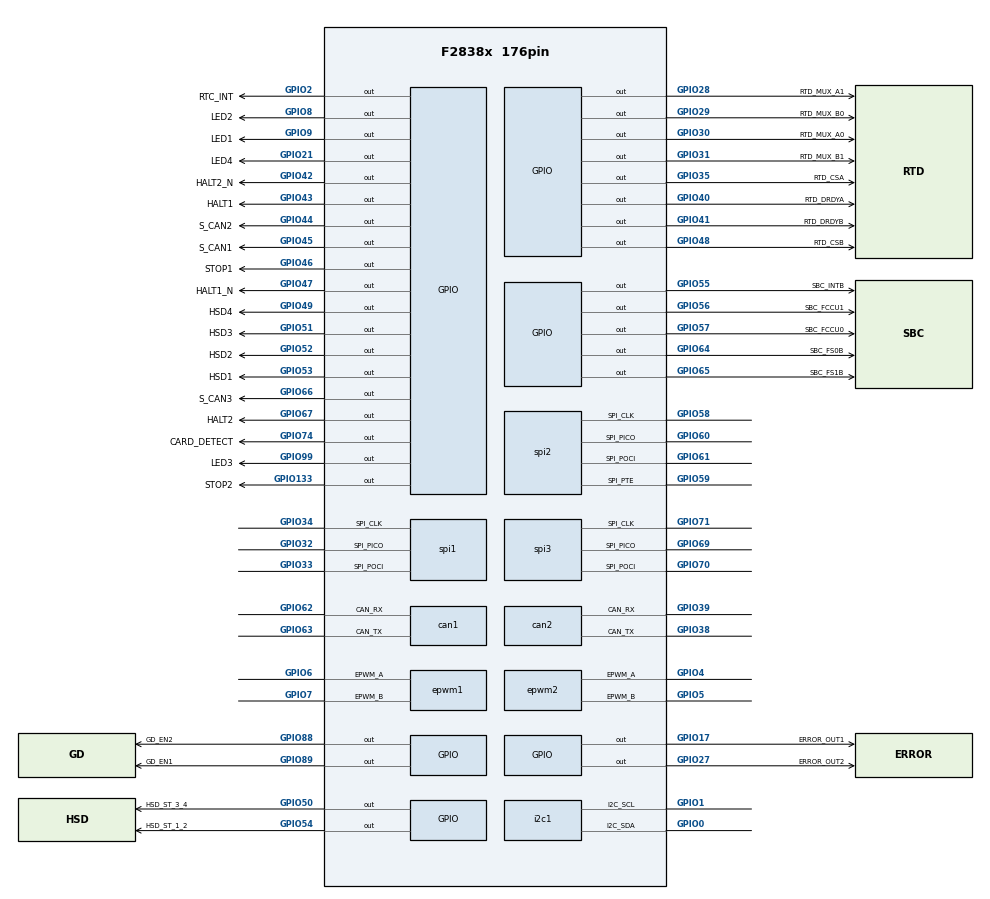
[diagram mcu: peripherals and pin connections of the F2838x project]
/**
 * @cliArgs --device "F2838x" --package "176pin" --part "F2838x_176pin" --context "CPU1" --product "C2000WARE@5.02.00.00"
 * @versions {"tool":"1.19.0+3426"}
 */

/**
 * Import the modules used in this configuration.
 */
const adc            = scripting.addModule("/driverlib/adc.js", {}, false);
const adc1           = adc.addInstance();
const adc2           = adc.addInstance();
const adc3           = adc.addInstance();
const adc4           = adc.addInstance();
const asysctl        = scripting.addModule("/driverlib/asysctl.js");
const can            = scripting.addModule("/driverlib/can.js", {}, false);
const can1           = can.addInstance();
const can2           = can.addInstance();
const cla            = scripting.addModule("/driverlib/cla.js", {}, false);
const cla1           = cla.addInstance();
const device_support = scripting.addModule("/driverlib/device_support.js");
const epwm           = scripting.addModule("/driverlib/epwm.js", {}, false);
const epwm1          = epwm.addInstance();
const epwm2          = epwm.addInstance();
const epwm3          = epwm.addInstance();
const epwm4          = epwm.addInstance();
const gpio           = scripting.addModule("/driverlib/gpio.js", {}, false);
const gpio1          = gpio.addInstance();
const gpio2          = gpio.addInstance();
const gpio3          = gpio.addInstance();
const gpio4          = gpio.addInstance();
const gpio5          = gpio.addInstance();
const gpio6          = gpio.addInstance();
const gpio7          = gpio.addInstance();
const gpio8          = gpio.addInstance();
const gpio9          = gpio.addInstance();
const gpio10         = gpio.addInstance();
const gpio11         = gpio.addInstance();
const gpio12         = gpio.addInstance();
const gpio13         = gpio.addInstance();
const gpio14         = gpio.addInstance();
const gpio15         = gpio.addInstance();
const gpio16         = gpio.addInstance();
const gpio17         = gpio.addInstance();
const gpio18         = gpio.addInstance();
const gpio19         = gpio.addInstance();
const gpio20         = gpio.addInstance();
const gpio21         = gpio.addInstance();
const gpio22         = gpio.addInstance();
const gpio23         = gpio.addInstance();
const gpio24         = gpio.addInstance();
const gpio25         = gpio.addInstance();
const gpio26         = gpio.addInstance();
const gpio27         = gpio.addInstance();
const gpio28         = gpio.addInstance();
const gpio29         = gpio.addInstance();
const gpio30         = gpio.addInstance();
const gpio31         = gpio.addInstance();
const gpio32         = gpio.addInstance();
const gpio33         = gpio.addInstance();
const gpio34         = gpio.addInstance();
const gpio35         = gpio.addInstance();
const gpio36         = gpio.addInstance();
const gpio37         = gpio.addInstance();
const gpio38         = gpio.addInstance();
const i2c            = scripting.addModule("/driverlib/i2c.js", {}, false);
const i2c1           = i2c.addInstance();
const ipc            = scripting.addModule("/driverlib/ipc.js");
const memcfg         = scripting.addModule("/driverlib/memcfg.js");
const spi            = scripting.addModule("/driverlib/spi.js", {}, false);
const spi1           = spi.addInstance();
const spi2           = spi.addInstance();
const spi3           = spi.addInstance();
const sync           = scripting.addModule("/driverlib/sync.js");
const sysctl         = scripting.addModule("/driverlib/sysctl.js");
const FREERTOS       = scripting.addModule("/kernel/freertos_tool/FREERTOS", {}, false);
const FREERTOS1      = FREERTOS.addInstance();
const FPUfastRTS     = scripting.addModule("/libraries/math/FPUfastRTS/FPUfastRTS.js", {}, false);
const FPUfastRTS1    = FPUfastRTS.addInstance();
const CMD            = scripting.addModule("/utilities/cmd_tool/cmd_syscfg/source/CMD");
const CMD1           = CMD.addInstance();

/**
 * Write custom configuration values to the imported modules.
 */
adc1.$name                   = "myADCA";
adc1.adcClockPrescaler       = "ADC_CLK_DIV_4_0";
adc1.adcResolutionMode       = "ADC_RESOLUTION_16BIT";
adc1.adcSignalMode           = "ADC_MODE_DIFFERENTIAL";
adc1.socHighPriorityMode     = "ADC_PRI_ALL_HIPRI";
adc1.enabledSOCs             = ["ADC_SOC_NUMBER0","ADC_SOC_NUMBER1"];
adc1.soc0Channel             = "ADC_CH_ADCIN2_ADCIN3";
adc1.soc0Trigger             = "ADC_TRIGGER_EPWM4_SOCA";
adc1.soc0SampleWindow        = 96;
adc1.soc1Channel             = "ADC_CH_ADCIN4_ADCIN5";
adc1.soc1Trigger             = "ADC_TRIGGER_EPWM4_SOCA";
adc1.soc1SampleWindow        = 96;
adc1.interruptPulseMode      = "ADC_PULSE_END_OF_CONV";
adc1.enabledInts             = ["ADC_INT_NUMBER1"];
adc1.enableInterrupt1        = true;
adc1.interrupt1SOCSource     = "ADC_SOC_NUMBER1";
adc1.registerInterrupts      = ["1"];
adc1.adcInt1.enableInterrupt = true;

adc2.$name                   = "myADCB";
adc2.adcBase                 = "ADCB_BASE";
adc2.adcClockPrescaler       = "ADC_CLK_DIV_4_0";
adc2.adcResolutionMode       = "ADC_RESOLUTION_16BIT";
adc2.socHighPriorityMode     = "ADC_PRI_ALL_HIPRI";
adc2.enabledSOCs             = ["ADC_SOC_NUMBER0","ADC_SOC_NUMBER1","ADC_SOC_NUMBER2","ADC_SOC_NUMBER3"];
adc2.soc0Channel             = "ADC_CH_ADCIN3";
adc2.soc0Trigger             = "ADC_TRIGGER_EPWM4_SOCA";
adc2.soc0SampleWindow        = 96;
adc2.soc1SampleWindow        = 96;
adc2.soc1Trigger             = "ADC_TRIGGER_EPWM4_SOCA";
adc2.soc1Channel             = "ADC_CH_ADCIN8";
adc2.soc2Channel             = "ADC_CH_ADCIN2";
adc2.soc2SampleWindow        = 96;
adc2.soc2Trigger             = "ADC_TRIGGER_EPWM4_SOCA";
adc2.soc3Channel             = "ADC_CH_ADCIN9";
adc2.soc3Trigger             = "ADC_TRIGGER_EPWM4_SOCA";
adc2.soc3SampleWindow        = 96;
adc2.interruptPulseMode      = "ADC_PULSE_END_OF_CONV";
adc2.enabledInts             = ["ADC_INT_NUMBER1"];
adc2.enableInterrupt1        = true;
adc2.interrupt1SOCSource     = "ADC_SOC_NUMBER3";
adc2.registerInterrupts      = ["1"];
adc2.adcInt1.enableInterrupt = true;

adc3.$name                   = "myADCC";
adc3.adcBase                 = "ADCC_BASE";
adc3.adcClockPrescaler       = "ADC_CLK_DIV_4_0";
adc3.adcResolutionMode       = "ADC_RESOLUTION_16BIT";
adc3.adcSignalMode           = "ADC_MODE_DIFFERENTIAL";
adc3.socHighPriorityMode     = "ADC_PRI_ALL_HIPRI";
adc3.enabledSOCs             = ["ADC_SOC_NUMBER0","ADC_SOC_NUMBER1"];
adc3.soc0Channel             = "ADC_CH_ADCIN2_ADCIN3";
adc3.soc0SampleWindow        = 96;
adc3.soc0Trigger             = "ADC_TRIGGER_EPWM4_SOCA";
adc3.soc1Channel             = "ADC_CH_ADCIN4_ADCIN5";
adc3.soc1SampleWindow        = 96;
adc3.soc1Trigger             = "ADC_TRIGGER_EPWM4_SOCA";
adc3.interruptPulseMode      = "ADC_PULSE_END_OF_CONV";
adc3.enabledInts             = ["ADC_INT_NUMBER1"];
adc3.enableInterrupt1        = true;
adc3.interrupt1SOCSource     = "ADC_SOC_NUMBER1";
adc3.registerInterrupts      = ["1"];
adc3.adcInt1.enableInterrupt = true;

adc4.adcBase                 = "ADCD_BASE";
adc4.$name                   = "myADCD";
adc4.adcClockPrescaler       = "ADC_CLK_DIV_4_0";
adc4.adcResolutionMode       = "ADC_RESOLUTION_16BIT";
adc4.socHighPriorityMode     = "ADC_PRI_ALL_HIPRI";
adc4.enabledSOCs             = ["ADC_SOC_NUMBER0","ADC_SOC_NUMBER1","ADC_SOC_NUMBER2","ADC_SOC_NUMBER3","ADC_SOC_NUMBER4","ADC_SOC_NUMBER5"];
adc4.soc0Channel             = "ADC_CH_ADCIN1";
adc4.soc0Trigger             = "ADC_TRIGGER_EPWM4_SOCA";
adc4.soc0SampleWindow        = 96;
adc4.soc1Channel             = "ADC_CH_ADCIN8";
adc4.soc1SampleWindow        = 96;
adc4.soc1Trigger             = "ADC_TRIGGER_EPWM4_SOCA";
adc4.soc2SampleWindow        = 96;
adc4.soc2Trigger             = "ADC_TRIGGER_EPWM4_SOCA";
adc4.soc3Trigger             = "ADC_TRIGGER_EPWM4_SOCA";
adc4.soc3SampleWindow        = 96;
adc4.soc3Channel             = "ADC_CH_ADCIN9";
adc4.soc4Channel             = "ADC_CH_ADCIN2";
adc4.soc4Trigger             = "ADC_TRIGGER_EPWM4_SOCA";
adc4.soc4SampleWindow        = 96;
adc4.soc5Channel             = "ADC_CH_ADCIN9";
adc4.soc5SampleWindow        = 96;
adc4.soc5Trigger             = "ADC_TRIGGER_EPWM4_SOCA";
adc4.interruptPulseMode      = "ADC_PULSE_END_OF_CONV";
adc4.enabledInts             = ["ADC_INT_NUMBER1"];
adc4.enableInterrupt1        = true;
adc4.registerInterrupts      = ["1"];
adc4.interrupt1SOCSource     = "ADC_SOC_NUMBER5";
adc4.adcInt1.enableInterrupt = true;

asysctl.enableTemperatureSensor = true;

can1.msgObjsUsed           = [1,2,3,4,5,6];
can1.registerInterrupts    = true;
can1.interruptFlags        = ["CAN_INT_ERROR","CAN_INT_IE0","CAN_INT_STATUS"];
can1.interruptLine         = ["CAN_GLOBAL_INT_CANINT0"];
can1.$name                 = "CAN1";
can1.can.$assign           = "CANA";
can1.can.can_rxPin.$assign = "GPIO62";
can1.can.can_txPin.$assign = "GPIO63";
can1.msgObj1.$name         = "msgObj0";
can1.msgObj1.msgID         = 1580;
can1.msgObj1.msgType       = "CAN_MSG_OBJ_TYPE_TX";
can1.msgObj1.flags         = ["CAN_MSG_OBJ_TX_INT_ENABLE"];
can1.msgObj1.msgLen        = 8;
can1.msgObj2.$name         = "msgObj1";
can1.msgObj2.msgID         = 1452;
can1.msgObj2.flags         = ["CAN_MSG_OBJ_RX_INT_ENABLE"];
can1.msgObj3.$name         = "msgObj2";
can1.msgObj3.msgID         = 1581;
can1.msgObj3.msgType       = "CAN_MSG_OBJ_TYPE_TX";
can1.msgObj3.flags         = ["CAN_MSG_OBJ_TX_INT_ENABLE"];
can1.msgObj3.msgLen        = 8;
can1.msgObj4.$name         = "msgObj3";
can1.msgObj4.msgID         = 1453;
can1.msgObj4.flags         = ["CAN_MSG_OBJ_RX_INT_ENABLE"];
can1.msgObj5.$name         = "msgObj4";
can1.msgObj5.msgID         = 1836;
can1.msgObj5.flags         = ["CAN_MSG_OBJ_RX_INT_ENABLE"];
can1.msgObj6.$name         = "msgObj5";
can1.msgObj6.msgID         = 1837;
can1.msgObj6.flags         = ["CAN_MSG_OBJ_RX_INT_ENABLE"];

can2.msgObjsUsed           = [1,2,3,4,5,6,7,8,9,10,11,12,13,14,15,16];
can2.enableInterrupt       = true;
can2.registerInterrupts    = true;
can2.interruptFlags        = ["CAN_INT_ERROR","CAN_INT_IE0","CAN_INT_STATUS"];
can2.interruptLine         = ["CAN_GLOBAL_INT_CANINT0"];
can2.$name                 = "CAN2";
can2.can.$assign           = "CANB";
can2.can.can_rxPin.$assign = "GPIO39";
can2.can.can_txPin.$assign = "GPIO38";
can2.msgObj1.$name         = "msgObj6";
can2.msgObj1.msgID         = 660;
can2.msgObj1.flags         = ["CAN_MSG_OBJ_RX_INT_ENABLE"];
can2.msgObj2.$name         = "msgObj7";
can2.msgObj2.msgID         = 661;
can2.msgObj2.flags         = ["CAN_MSG_OBJ_RX_INT_ENABLE"];
can2.msgObj3.$name         = "msgObj8";
can2.msgObj3.msgID         = 662;
can2.msgObj3.msgType       = "CAN_MSG_OBJ_TYPE_TX";
can2.msgObj3.flags         = ["CAN_MSG_OBJ_TX_INT_ENABLE"];
can2.msgObj3.msgLen        = 8;
can2.msgObj4.$name         = "msgObj9";
can2.msgObj4.msgID         = 663;
can2.msgObj4.flags         = ["CAN_MSG_OBJ_RX_INT_ENABLE"];
can2.msgObj5.$name         = "msgObj12";
can2.msgObj5.msgID         = 664;
can2.msgObj5.msgType       = "CAN_MSG_OBJ_TYPE_TX";
can2.msgObj5.flags         = ["CAN_MSG_OBJ_TX_INT_ENABLE"];
can2.msgObj5.msgLen        = 8;
can2.msgObj6.$name         = "msgObj10";
can2.msgObj6.msgID         = 665;
can2.msgObj6.msgType       = "CAN_MSG_OBJ_TYPE_TX";
can2.msgObj6.flags         = ["CAN_MSG_OBJ_TX_INT_ENABLE"];
can2.msgObj6.msgLen        = 8;
can2.msgObj7.$name         = "msgObj11";
can2.msgObj7.msgID         = 666;
can2.msgObj7.msgType       = "CAN_MSG_OBJ_TYPE_TX";
can2.msgObj7.msgLen        = 8;
can2.msgObj7.flags         = ["CAN_MSG_OBJ_TX_INT_ENABLE"];
can2.msgObj8.$name         = "msgObj13";
can2.msgObj8.msgID         = 667;
can2.msgObj8.msgType       = "CAN_MSG_OBJ_TYPE_TX";
can2.msgObj8.flags         = ["CAN_MSG_OBJ_TX_INT_ENABLE"];
can2.msgObj8.msgLen        = 8;
can2.msgObj9.$name         = "msgObj14";
can2.msgObj9.msgID         = 668;
can2.msgObj9.msgType       = "CAN_MSG_OBJ_TYPE_TX";
can2.msgObj9.flags         = ["CAN_MSG_OBJ_TX_INT_ENABLE"];
can2.msgObj9.msgLen        = 6;
can2.msgObj10.$name        = "msgObj15";
can2.msgObj10.msgID        = 669;
can2.msgObj10.msgType      = "CAN_MSG_OBJ_TYPE_TX";
can2.msgObj10.flags        = ["CAN_MSG_OBJ_TX_INT_ENABLE"];
can2.msgObj10.msgLen       = 6;
can2.msgObj11.$name        = "msgObj16";
can2.msgObj11.msgID        = 670;
can2.msgObj11.msgType      = "CAN_MSG_OBJ_TYPE_TX";
can2.msgObj11.flags        = ["CAN_MSG_OBJ_TX_INT_ENABLE"];
can2.msgObj11.msgLen       = 7;
can2.msgObj12.$name        = "msgObj18";
can2.msgObj12.msgID        = 671;
can2.msgObj12.msgType      = "CAN_MSG_OBJ_TYPE_TX";
can2.msgObj12.flags        = ["CAN_MSG_OBJ_TX_INT_ENABLE"];
can2.msgObj12.msgLen       = 7;
can2.msgObj13.$name        = "msgObj17";
can2.msgObj13.msgID        = 672;
can2.msgObj13.msgType      = "CAN_MSG_OBJ_TYPE_TX";
can2.msgObj13.flags        = ["CAN_MSG_OBJ_TX_INT_ENABLE"];
can2.msgObj13.msgLen       = 8;
can2.msgObj14.$name        = "msgObj19";
can2.msgObj14.msgID        = 673;
can2.msgObj14.msgType      = "CAN_MSG_OBJ_TYPE_TX";
can2.msgObj14.flags        = ["CAN_MSG_OBJ_TX_INT_ENABLE"];
can2.msgObj14.msgLen       = 8;
can2.msgObj15.$name        = "msgObj20";
can2.msgObj15.msgID        = 674;
can2.msgObj15.msgType      = "CAN_MSG_OBJ_TYPE_TX";
can2.msgObj15.flags        = ["CAN_MSG_OBJ_TX_INT_ENABLE"];
can2.msgObj15.msgLen       = 8;
can2.msgObj16.$name        = "msgObj21";
can2.msgObj16.msgID        = 675;
can2.msgObj16.msgType      = "CAN_MSG_OBJ_TYPE_TX";
can2.msgObj16.flags        = ["CAN_MSG_OBJ_TX_INT_ENABLE"];
can2.msgObj16.msgLen       = 8;

cla1.$name = "myCLA0";

const multiplier1         = system.clockTree["AUX_IMULT"];
multiplier1.multiplyValue = 50;

const multiplier2         = system.clockTree["PLL_IMULT"];
multiplier2.multiplyValue = 40;

const mux18       = system.clockTree["XTAL_OR_X1"];
mux18.inputSelect = "XTAL";

const pinFunction3     = system.clockTree["XTAL"];
pinFunction3.XTAL_Freq = 20;

epwm1.$name                                                      = "GD_HB_1";
epwm1.epwmTimebase_hsClockDiv                                    = "EPWM_HSCLOCK_DIVIDER_1";
epwm1.epwmTimebase_period                                        = 25000;
epwm1.epwmTimebase_counterValue                                  = 17000;
epwm1.epwmTimebase_counterMode                                   = "EPWM_COUNTER_MODE_UP_DOWN";
epwm1.epwmTimebase_syncInPulseSource                             = "EPWM_SYNC_IN_PULSE_SRC_DISABLE";
epwm1.epwmTimebase_syncOutPulseMode                              = ["EPWM_SYNC_OUT_PULSE_ON_SOFTWARE"];
epwm1.epwmCounterCompare_cmpA                                    = 1000;
epwm1.epwmCounterCompare_cmpB                                    = 1000;
epwm1.epwmActionQualifier_EPWM_AQ_OUTPUT_A_shadowMode            = true;
epwm1.epwmActionQualifier_EPWM_AQ_OUTPUT_A_ON_TIMEBASE_UP_CMPA   = "EPWM_AQ_OUTPUT_HIGH";
epwm1.epwmActionQualifier_EPWM_AQ_OUTPUT_A_ON_TIMEBASE_DOWN_CMPB = "EPWM_AQ_OUTPUT_LOW";
epwm1.epwmActionQualifier_EPWM_AQ_OUTPUT_B_shadowMode            = true;
epwm1.epwmActionQualifier_EPWM_AQ_OUTPUT_B_ON_TIMEBASE_UP_CMPA   = "EPWM_AQ_OUTPUT_LOW";
epwm1.epwmActionQualifier_EPWM_AQ_OUTPUT_B_ON_TIMEBASE_DOWN_CMPB = "EPWM_AQ_OUTPUT_HIGH";
epwm1.epwmDeadband_polarityFED                                   = "EPWM_DB_POLARITY_ACTIVE_LOW";
epwm1.epwmDeadband_enableRED                                     = true;
epwm1.epwmDeadband_delayRED                                      = 800;
epwm1.epwmDeadband_enableFED                                     = true;
epwm1.epwmDeadband_delayFED                                      = 800;
epwm1.epwmEventTrigger_enableInterrupt                           = true;
epwm1.epwmEventTrigger_registerInterrupts                        = true;
epwm1.epwmEventTrigger_interruptSource                           = "EPWM_INT_TBCTR_PERIOD";
epwm1.epwmEventTrigger_interruptEventCount                       = "1";
epwm1.epwmEventTrigger_EPWM_SOC_A_triggerEnable                  = true;
epwm1.epwmEventTrigger_EPWM_SOC_A_triggerSource                  = "EPWM_SOC_TBCTR_PERIOD";
epwm1.epwmEventTrigger_EPWM_SOC_A_triggerEventPrescalar          = "1";
epwm1.epwmEventTrigger_EPWM_SOC_B_triggerEnable                  = true;
epwm1.epwmEventTrigger_EPWM_SOC_B_triggerSource                  = "EPWM_SOC_TBCTR_PERIOD";
epwm1.epwmEventTrigger_EPWM_SOC_B_triggerEventPrescalar          = "1";
epwm1.epwmTripZone_EPWM_TZ_ACTION_EVENT_TZB                      = "EPWM_TZ_ACTION_LOW";
epwm1.epwmTripZone_oneShotSource                                 = ["EPWM_TZ_SIGNAL_OSHT1"];
epwm1.epwmTripZone_tzInterruptSource                             = ["EPWM_TZ_INTERRUPT_OST"];
epwm1.epwmTripZone_EPWM_TZ_ACTION_EVENT_TZA                      = "EPWM_TZ_ACTION_HIGH";
epwm1.epwm.$assign                                               = "EPWM4";
epwm1.epwm.epwm_aPin.$assign                                     = "GPIO6";
epwm1.epwm.epwm_bPin.$assign                                     = "GPIO7";
epwm1.epwmInt.enableInterrupt                                    = true;

epwm2.$name                                                      = "GD_HB_2";
epwm2.epwmTimebase_hsClockDiv                                    = "EPWM_HSCLOCK_DIVIDER_1";
epwm2.epwmTimebase_counterMode                                   = "EPWM_COUNTER_MODE_UP_DOWN";
epwm2.epwmTimebase_syncInPulseSource                             = "EPWM_SYNC_IN_PULSE_SRC_SYNCOUT_EPWM4";
epwm2.epwmTimebase_syncOutPulseMode                              = ["EPWM_SYNC_OUT_PULSE_ON_SOFTWARE"];
epwm2.epwmCounterCompare_cmpA                                    = 1000;
epwm2.epwmCounterCompare_cmpB                                    = 1000;
epwm2.epwmTimebase_period                                        = 2500;
epwm2.epwmDeadband_enableRED                                     = true;
epwm2.epwmDeadband_delayRED                                      = 560;
epwm2.epwmDeadband_delayFED                                      = 520;
epwm2.epwmDeadband_enableFED                                     = true;
epwm2.epwmDeadband_polarityFED                                   = "EPWM_DB_POLARITY_ACTIVE_LOW";
epwm2.epwmEventTrigger_enableInterrupt                           = true;
epwm2.epwmEventTrigger_registerInterrupts                        = true;
epwm2.epwmActionQualifier_EPWM_AQ_OUTPUT_A_ON_TIMEBASE_UP_CMPA   = "EPWM_AQ_OUTPUT_HIGH";
epwm2.epwmActionQualifier_EPWM_AQ_OUTPUT_A_ON_TIMEBASE_DOWN_CMPB = "EPWM_AQ_OUTPUT_LOW";
epwm2.epwmActionQualifier_EPWM_AQ_OUTPUT_A_shadowMode            = true;
epwm2.epwmActionQualifier_EPWM_AQ_OUTPUT_B_shadowMode            = true;
epwm2.epwmActionQualifier_EPWM_AQ_OUTPUT_B_ON_TIMEBASE_UP_CMPA   = "EPWM_AQ_OUTPUT_LOW";
epwm2.epwmActionQualifier_EPWM_AQ_OUTPUT_B_ON_TIMEBASE_DOWN_CMPB = "EPWM_AQ_OUTPUT_HIGH";
epwm2.epwmTripZone_EPWM_TZ_ACTION_EVENT_TZA                      = "EPWM_TZ_ACTION_LOW";
epwm2.epwmTripZone_oneShotSource                                 = ["EPWM_TZ_SIGNAL_OSHT1"];
epwm2.epwmTripZone_EPWM_TZ_ACTION_EVENT_TZB                      = "EPWM_TZ_ACTION_HIGH";
epwm2.epwm.$assign                                               = "EPWM3";
epwm2.epwm.epwm_aPin.$assign                                     = "GPIO4";
epwm2.epwm.epwm_bPin.$assign                                     = "GPIO5";
epwm2.epwmInt.enableInterrupt                                    = true;

epwm3.$name                                                      = "FO_HB_1";
epwm3.epwmTimebase_hsClockDiv                                    = "EPWM_HSCLOCK_DIVIDER_1";
epwm3.epwmTimebase_period                                        = 25000;
epwm3.epwmTimebase_counterMode                                   = "EPWM_COUNTER_MODE_UP_DOWN";
epwm3.epwmTimebase_syncInPulseSource                             = "EPWM_SYNC_IN_PULSE_SRC_SYNCOUT_EPWM4";
epwm3.epwmTimebase_syncOutPulseMode                              = ["EPWM_SYNC_OUT_PULSE_ON_SOFTWARE"];
epwm3.epwmCounterCompare_cmpA                                    = 1000;
epwm3.epwmCounterCompare_cmpB                                    = 1000;
epwm3.epwmEventTrigger_enableInterrupt                           = true;
epwm3.epwmEventTrigger_registerInterrupts                        = true;
epwm3.epwmEventTrigger_interruptEventCount                       = "1";
epwm3.epwmEventTrigger_interruptSource                           = "EPWM_INT_TBCTR_PERIOD";
epwm3.useCase                                                    = "CUSTOM";
epwm3.epwmDeadband_enableRED                                     = true;
epwm3.epwmDeadband_enableFED                                     = true;
epwm3.epwmDeadband_delayRED                                      = 560;
epwm3.epwmDeadband_delayFED                                      = 520;
epwm3.epwmDeadband_polarityRED                                   = "EPWM_DB_POLARITY_ACTIVE_LOW";
epwm3.epwmTripZone_EPWM_TZ_ACTION_EVENT_TZA                      = "EPWM_TZ_ACTION_LOW";
epwm3.epwmTripZone_EPWM_TZ_ACTION_EVENT_TZB                      = "EPWM_TZ_ACTION_HIGH";
epwm3.epwmActionQualifier_EPWM_AQ_OUTPUT_B_ON_TIMEBASE_UP_CMPA   = "EPWM_AQ_OUTPUT_HIGH";
epwm3.epwmActionQualifier_EPWM_AQ_OUTPUT_A_ON_TIMEBASE_UP_CMPA   = "EPWM_AQ_OUTPUT_LOW";
epwm3.epwmActionQualifier_EPWM_AQ_OUTPUT_A_ON_TIMEBASE_DOWN_CMPB = "EPWM_AQ_OUTPUT_HIGH";
epwm3.epwmActionQualifier_EPWM_AQ_OUTPUT_B_ON_TIMEBASE_DOWN_CMPB = "EPWM_AQ_OUTPUT_LOW";
epwm3.epwmActionQualifier_EPWM_AQ_OUTPUT_B_shadowMode            = true;
epwm3.epwmActionQualifier_EPWM_AQ_OUTPUT_A_shadowMode            = true;
epwm3.epwmInt.enableInterrupt                                    = true;
epwm3.epwm.$assign                                               = "EPWM12";

epwm4.$name                                                      = "FO_HB_2";
epwm4.epwmTimebase_hsClockDiv                                    = "EPWM_HSCLOCK_DIVIDER_1";
epwm4.epwmTimebase_period                                        = 25000;
epwm4.epwmTimebase_counterMode                                   = "EPWM_COUNTER_MODE_UP_DOWN";
epwm4.epwmTimebase_syncInPulseSource                             = "EPWM_SYNC_IN_PULSE_SRC_SYNCOUT_EPWM4";
epwm4.epwmTimebase_syncOutPulseMode                              = ["EPWM_SYNC_OUT_PULSE_ON_SOFTWARE"];
epwm4.epwmCounterCompare_cmpA                                    = 1000;
epwm4.epwmCounterCompare_cmpB                                    = 1000;
epwm4.epwmActionQualifier_EPWM_AQ_OUTPUT_A_shadowMode            = true;
epwm4.epwmActionQualifier_EPWM_AQ_OUTPUT_A_ON_TIMEBASE_UP_CMPA   = "EPWM_AQ_OUTPUT_LOW";
epwm4.epwmActionQualifier_EPWM_AQ_OUTPUT_A_ON_TIMEBASE_DOWN_CMPB = "EPWM_AQ_OUTPUT_HIGH";
epwm4.epwmActionQualifier_EPWM_AQ_OUTPUT_B_shadowMode            = true;
epwm4.epwmActionQualifier_EPWM_AQ_OUTPUT_B_ON_TIMEBASE_UP_CMPA   = "EPWM_AQ_OUTPUT_HIGH";
epwm4.epwmActionQualifier_EPWM_AQ_OUTPUT_B_ON_TIMEBASE_DOWN_CMPB = "EPWM_AQ_OUTPUT_LOW";
epwm4.epwmDeadband_enableRED                                     = true;
epwm4.epwmDeadband_delayRED                                      = 560;
epwm4.epwmDeadband_delayFED                                      = 520;
epwm4.epwmDeadband_enableFED                                     = true;
epwm4.epwmTripZone_EPWM_TZ_ACTION_EVENT_TZA                      = "EPWM_TZ_ACTION_LOW";
epwm4.epwmTripZone_EPWM_TZ_ACTION_EVENT_TZB                      = "EPWM_TZ_ACTION_HIGH";
epwm4.epwmTripZone_oneShotSource                                 = ["EPWM_TZ_SIGNAL_OSHT1"];
epwm4.epwmEventTrigger_enableInterrupt                           = true;
epwm4.epwmEventTrigger_registerInterrupts                        = true;
epwm4.epwmEventTrigger_EPWM_SOC_A_triggerEnable                  = true;
epwm4.epwmEventTrigger_EPWM_SOC_B_triggerEnable                  = true;
epwm4.epwmEventTrigger_EPWM_SOC_A_triggerEventPrescalar          = "1";
epwm4.epwmEventTrigger_EPWM_SOC_B_triggerEventPrescalar          = "1";
epwm4.useCase                                                    = "CUSTOM";
epwm4.epwmInt.enableInterrupt                                    = true;
epwm4.epwm.$assign                                               = "EPWM8";

gpio1.$name             = "LED1";
gpio1.direction         = "GPIO_DIR_MODE_OUT";
gpio1.writeInitialValue = true;
gpio1.initialValue      = 1;
gpio1.gpioPin.$assign   = "GPIO9";

gpio2.$name             = "LED2";
gpio2.direction         = "GPIO_DIR_MODE_OUT";
gpio2.controllerCore    = "GPIO_CORE_CPU2";
gpio2.writeInitialValue = true;
gpio2.initialValue      = 1;
gpio2.gpioPin.$assign   = "GPIO8";

gpio3.$name             = "LED3";
gpio3.direction         = "GPIO_DIR_MODE_OUT";
gpio3.writeInitialValue = true;
gpio3.initialValue      = 1;
gpio3.controllerCore    = "GPIO_CORE_CM";
gpio3.gpioPin.$assign   = "GPIO99";

gpio4.direction         = "GPIO_DIR_MODE_OUT";
gpio4.writeInitialValue = true;
gpio4.initialValue      = 1;
gpio4.$name             = "LED4";
gpio4.gpioPin.$assign   = "GPIO21";

gpio5.$name             = "RTD_CSA";
gpio5.direction         = "GPIO_DIR_MODE_OUT";
gpio5.writeInitialValue = true;
gpio5.initialValue      = 1;
gpio5.gpioPin.$assign   = "GPIO35";

gpio6.$name             = "RTD_CSB";
gpio6.direction         = "GPIO_DIR_MODE_OUT";
gpio6.writeInitialValue = true;
gpio6.initialValue      = 1;
gpio6.gpioPin.$assign   = "GPIO48";

gpio7.$name             = "RTD_MUX_A0";
gpio7.direction         = "GPIO_DIR_MODE_OUT";
gpio7.writeInitialValue = true;
gpio7.gpioPin.$assign   = "GPIO30";

gpio8.$name             = "RTD_MUX_A1";
gpio8.direction         = "GPIO_DIR_MODE_OUT";
gpio8.writeInitialValue = true;
gpio8.gpioPin.$assign   = "GPIO28";

gpio9.$name             = "RTD_MUX_B0";
gpio9.direction         = "GPIO_DIR_MODE_OUT";
gpio9.writeInitialValue = true;
gpio9.gpioPin.$assign   = "GPIO29";

gpio10.$name             = "RTD_MUX_B1";
gpio10.direction         = "GPIO_DIR_MODE_OUT";
gpio10.writeInitialValue = true;
gpio10.gpioPin.$assign   = "GPIO31";

gpio11.$name           = "RTD_DRDYA";
gpio11.gpioPin.$assign = "GPIO40";

gpio12.$name           = "RTD_DRDYB";
gpio12.gpioPin.$assign = "GPIO41";

gpio13.$name             = "GD_EN1";
gpio13.direction         = "GPIO_DIR_MODE_OUT";
gpio13.writeInitialValue = true;
gpio13.gpioPin.$assign   = "GPIO89";

gpio14.$name           = "GD_EN2";
gpio14.direction       = "GPIO_DIR_MODE_OUT";
gpio14.gpioPin.$assign = "GPIO88";

gpio15.$name           = "ERROR_OUT1";
gpio15.gpioPin.$assign = "GPIO17";

gpio16.$name           = "ERROR_OUT2";
gpio16.gpioPin.$assign = "GPIO27";

gpio17.$name           = "HALT1";
gpio17.gpioPin.$assign = "GPIO43";

gpio18.$name           = "HALT2";
gpio18.gpioPin.$assign = "GPIO67";

gpio19.$name           = "HALT1_N";
gpio19.gpioPin.$assign = "GPIO47";

gpio20.$name           = "HALT2_N";
gpio20.gpioPin.$assign = "GPIO42";

gpio21.$name           = "STOP1";
gpio21.direction       = "GPIO_DIR_MODE_OUT";
gpio21.gpioPin.$assign = "GPIO46";

gpio22.$name           = "STOP2";
gpio22.direction       = "GPIO_DIR_MODE_OUT";
gpio22.gpioPin.$assign = "GPIO133";

gpio23.$name             = "HSD1";
gpio23.direction         = "GPIO_DIR_MODE_OUT";
gpio23.writeInitialValue = true;
gpio23.gpioPin.$assign   = "GPIO53";

gpio24.$name             = "HSD2";
gpio24.direction         = "GPIO_DIR_MODE_OUT";
gpio24.writeInitialValue = true;
gpio24.gpioPin.$assign   = "GPIO52";

gpio25.$name             = "HSD3";
gpio25.direction         = "GPIO_DIR_MODE_OUT";
gpio25.writeInitialValue = true;
gpio25.gpioPin.$assign   = "GPIO51";

gpio26.$name             = "HSD4";
gpio26.direction         = "GPIO_DIR_MODE_OUT";
gpio26.writeInitialValue = true;
gpio26.gpioPin.$assign   = "GPIO49";

gpio27.$name           = "HSD_ST_1_2";
gpio27.gpioPin.$assign = "GPIO54";

gpio28.$name           = "HSD_ST_3_4";
gpio28.gpioPin.$assign = "GPIO50";

gpio29.$name           = "CARD_DETECT";
gpio29.gpioPin.$assign = "GPIO74";

gpio30.$name             = "S_CAN1";
gpio30.direction         = "GPIO_DIR_MODE_OUT";
gpio30.controllerCore    = "GPIO_CORE_CM";
gpio30.writeInitialValue = true;
gpio30.gpioPin.$assign   = "GPIO45";

gpio31.$name           = "S_CAN2";
gpio31.direction       = "GPIO_DIR_MODE_OUT";
gpio31.gpioPin.$assign = "GPIO44";

gpio32.$name             = "S_CAN3";
gpio32.direction         = "GPIO_DIR_MODE_OUT";
gpio32.controllerCore    = "GPIO_CORE_CM";
gpio32.writeInitialValue = true;
gpio32.initialValue      = 1;
gpio32.gpioPin.$assign   = "GPIO66";

gpio33.$name           = "RTC_INT";
gpio33.gpioPin.$assign = "GPIO2";

gpio34.$name           = "SBC_INTB";
gpio34.gpioPin.$assign = "GPIO55";

gpio35.$name           = "SBC_FS0B";
gpio35.gpioPin.$assign = "GPIO64";

gpio36.$name           = "SBC_FS1B";
gpio36.gpioPin.$assign = "GPIO65";

gpio37.$name           = "SBC_FCCU0";
gpio37.gpioPin.$assign = "GPIO57";

gpio38.$name           = "SBC_FCCU1";
gpio38.gpioPin.$assign = "GPIO56";

i2c1.$name                  = "I2C_RTC";
i2c1.duty                   = "I2C_DUTYCYCLE_50";
i2c1.bitCount               = "I2C_BITCOUNT_8";
i2c1.dataCount              = 2;
i2c1.targetAddress          = 0x51;
i2c1.enabledInterrupts      = ["I2C_INT_ADDR_TARGET","I2C_INT_ARB_LOST","I2C_INT_NO_ACK","I2C_INT_STOP_CONDITION"];
i2c1.emulationMode          = "I2C_EMULATION_FREE_RUN";
i2c1.i2c.$assign            = "I2CA";
i2c1.i2c.i2c_sdaPin.$assign = "GPIO0";
i2c1.i2c.i2c_sclPin.$assign = "GPIO1";
i2c1.sdaQual.padConfig      = "STD";
i2c1.sclQual.padConfig      = "STD";

ipc.registerInterrupts       = ["0","1","2","3"];
ipc.ipcRegisterFlag          = ["IPC_FLAG0","IPC_FLAG1","IPC_FLAG2","IPC_FLAG3","IPC_FLAG31"];
ipc.enableInterrupt0         = true;
ipc.enableInterrupt1         = true;
ipc.enableInterrupt2         = true;
ipc.enableInterrupt3         = true;
ipc.flagHandler3             = "IPC_RESET_FLAG";
ipc.flagHandler31            = "IPC_SYNC_FLAG";
ipc.ipcInt0.interruptHandler = "IPC_CPU2_ISR0";
ipc.ipcInt0.enableInterrupt  = true;
ipc.ipcInt1.enableInterrupt  = true;
ipc.ipcInt1.interruptHandler = "IPC_CPU2_ISR1";
ipc.ipcInt2.interruptHandler = "IPC_CPU2_ISR2";
ipc.ipcInt2.enableInterrupt  = true;
ipc.ipcInt3.enableInterrupt  = true;
ipc.ipcInt3.interruptHandler = "IPC_CPU2_ISR0";

memcfg.init_MEMCFG_SECT_MSGCPUTOCPU1 = true;
memcfg.init_MEMCFG_SECT_MSGCPUTOCM0  = true;
memcfg.init_MEMCFG_SECT_MSGCPUTOCM1  = true;
memcfg.config_MEMCFG_SECT_LS6        = "CLA_prog";
memcfg.config_MEMCFG_SECT_LS7        = "CLA_prog";
memcfg.config_MEMCFG_SECT_LS5        = "CLA_data";
memcfg.init_MEMCFG_SECT_MSGCPUTOCPU0 = true;
memcfg.init_MEMCFG_SECT_MSGCPUTOCLA1 = true;
memcfg.init_MEMCFG_SECT_MSGCLA1TOCPU = true;

spi1.$name                   = "RTD_SPI";
spi1.useInterrupts           = false;
spi1.useFifo                 = false;
spi1.useCase                 = "CUSTOM";
spi1.useInterfacePins        = ["SPI@_CLK","SPI@_SIMO","SPI@_SOMI"];
spi1.mode                    = "SPI_MODE_CONTROLLER";
spi1.spi.$assign             = "SPIA";
spi1.spi.spi_picoPin.$assign = "GPIO32";
spi1.spi.spi_pociPin.$assign = "GPIO33";
spi1.spi.spi_clkPin.$assign  = "GPIO34";

spi2.$name                   = "SBC_SPI";
spi2.spi.$assign             = "SPIB";
spi2.spi.spi_picoPin.$assign = "GPIO60";
spi2.spi.spi_pociPin.$assign = "GPIO61";
spi2.spi.spi_clkPin.$assign  = "GPIO58";
spi2.spi.spi_ptePin.$assign  = "GPIO59";

spi3.$name                   = "SD_SPI";
spi3.transferProtocol        = "SPI_PROT_POL0PHA1";
spi3.mode                    = "SPI_MODE_CONTROLLER";
spi3.useCase                 = "CUSTOM";
spi3.useInterfacePins        = ["SPI@_CLK","SPI@_SIMO","SPI@_SOMI"];
spi3.spi.$assign             = "SPIC";
spi3.spi.spi_picoPin.$assign = "GPIO69";
spi3.spi.spi_pociPin.$assign = "GPIO70";
spi3.spi.spi_clkPin.$assign  = "GPIO71";

sync.syncOutSource = "SYSCTL_SYNC_OUT_SRC_EPWM4SYNCOUT";

sysctl.sharedPeripheralAllocate_SYSCTL_PALLOCATE_MCAN_A = true;
sysctl.sharedPeripheralAllocate_SYSCTL_PALLOCATE_CAN_A  = true;

FREERTOS1.$name                    = "myFREERTOS0";
FREERTOS1.CPU_CLOCK_HZ             = 200000000;
FREERTOS1.MAX_PRIORITIES           = 32;
FREERTOS1.MINIMAL_STACK_SIZE       = 256;
FREERTOS1.MAX_TASK_NAME_LEN        = 10;
FREERTOS1.USE_TICK_HOOK            = true;
FREERTOS1.CHECK_FOR_STACK_OVERFLOW = 2;
FREERTOS1.USE_MALLOC_FAILED_HOOK   = true;

FPUfastRTS1.$name = "myFFR0";

CMD.activateCMD = true;
CMD.activeCMD   = "CMD_Config";

CMD1.$name                                 = "CMD_Config";
CMD1.sectionMemory_codestart               = "0x080000";
CMD1.sectionMemory_text                    = ["FLASH1","FLASH2","FLASH3","FLASH4"];
CMD1.sectionAlignEnable_text               = true;
CMD1.sectionMemory_ramfunc                 = ["FLASH3"];
CMD1.sectionAlignEnable_ramfunc            = true;
CMD1.sectionRunFromDifferentAddr_ramfunc   = true;
CMD1.sectionRun_ramfunc                    = ["RAMLS0_4"];
CMD1.sectionBinit_ramfunc                  = false;
CMD1.sectionMemory_binit                   = ["FLASH4"];
CMD1.sectionAlignEnable_binit              = true;
CMD1.sectionMemory_ovly                    = ["FLASH0"];
CMD1.sectionAlignEnable_ovly               = true;
CMD1.sectionMemory_cinit                   = ["FLASH4"];
CMD1.sectionAlignEnable_cinit              = true;
CMD1.sectionMemory_stack                   = ["RAMM1"];
CMD1.sectionMemory_init_array              = ["FLASH1"];
CMD1.sectionAlignEnable_init_array         = true;
CMD1.sectionMemory_bss                     = ["RAMLS0_4"];
CMD1.sectionMemory_const                   = ["FLASH5"];
CMD1.sectionAlignEnable_const              = true;
CMD1.sectionMemory_data                    = ["RAMLS0_4"];
CMD1.sectionMemory_switch                  = ["FLASH1"];
CMD1.sectionAlignEnable_switch             = true;
CMD1.sectionMemory_sysmem                  = ["RAMLS0_4"];
CMD1.sectionMemory_cla1Prog                = ["FLASH13"];
CMD1.sectionRunFromDifferentAddr_cla1Prog  = true;
CMD1.sectionBinit_cla1Prog                 = false;
CMD1.sectionAlignEnable_cla1Prog           = true;
CMD1.sectionRun_cla1Prog                   = ["RAMLS6_7"];
CMD1.sectionMemory_claConst                = ["FLASH13"];
CMD1.sectionRunFromDifferentAddr_claConst  = true;
CMD1.sectionRun_claConst                   = ["RAMLS5"];
CMD1.sectionAlignEnable_claConst           = true;
CMD1.sectionMemory_claScratchpad           = ["RAMLS5"];
CMD1.sectionMemory_bssCla                  = ["RAMLS5"];
CMD1.sectionMemory_cla1ToCpuMsgRAM         = ["CLATOCPU_MSGRAM"];
CMD1.sectionMemory_cpuToCla1MsgRAM         = ["CPUTOCLA_MSGRAM"];
CMD1.RAMLSmemoryCombination.create(2);
CMD1.RAMLSmemoryCombination[0].$name       = "RAMLS0_4";
CMD1.RAMLSmemoryCombination[0].combination = ["RAMLS0","RAMLS1","RAMLS2","RAMLS3","RAMLS4"];
CMD1.RAMLSmemoryCombination[1].$name       = "RAMLS6_7";
CMD1.RAMLSmemoryCombination[1].combination = ["RAMLS6","RAMLS7"];
CMD1.userSection.create(3);
CMD1.userSection[0].$name                  = "freertos_stack_mem";
CMD1.userSection[0].sectionName            = ".freertosStaticStack";
CMD1.userSection[0].sectionMemory          = ["RAMLS0_4"];
CMD1.userSection[1].$name                  = "cla_memory_cpu_init_mem";
CMD1.userSection[1].sectionName            = "cla_memory_cpu_init";
CMD1.userSection[1].sectionMemory          = ["RAMLS5"];
CMD1.userSection[2].$name                  = "freertos_heap_mem";
CMD1.userSection[2].sectionName            = ".freertosHeap";
CMD1.userSection[2].sectionMemory          = ["RAMLS0_4"];
scripting.suppress("Memcfg module must be enabled for complete error checking\\.", CMD1, "sectionMemory_cpuToCla1MsgRAM");
